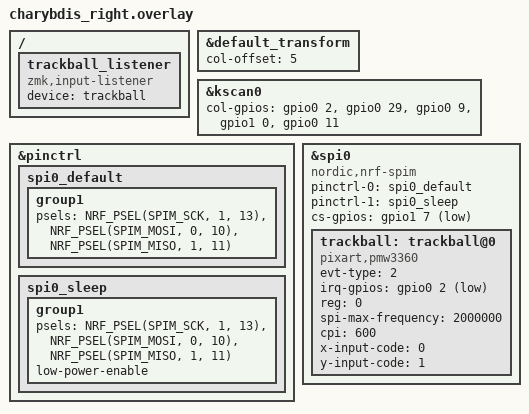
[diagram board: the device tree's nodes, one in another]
// charybdis_right.overlay

#include "charybdis.dtsi"

&default_transform { // The matrix transform for this board is 6 columns over because the left half is 6 columns wide according to the matrix.
    col-offset = <5>;
};

&kscan0 {
    col-gpios
        = <&gpio0 2  (GPIO_ACTIVE_HIGH | GPIO_PULL_DOWN)> // col0 in the schematic
        , <&gpio0 29  (GPIO_ACTIVE_HIGH | GPIO_PULL_DOWN)> // col1 in the schematic
        , <&gpio0 9 (GPIO_ACTIVE_HIGH | GPIO_PULL_DOWN)> // col2 in the schematic
        , <&gpio1 0  (GPIO_ACTIVE_HIGH | GPIO_PULL_DOWN)> // col3 in the schematic
        , <&gpio0 11 (GPIO_ACTIVE_HIGH | GPIO_PULL_DOWN)> // col4 in the schematic
        ;
};


&pinctrl {
    spi0_default: spi0_default {
        group1 {
            psels = <NRF_PSEL(SPIM_SCK, 1, 13)>,
                    <NRF_PSEL(SPIM_MOSI, 0, 10)>,
                    <NRF_PSEL(SPIM_MISO, 1, 11)>;
        };
    };

    spi0_sleep: spi0_sleep {
        group1 {
            psels = <NRF_PSEL(SPIM_SCK, 1, 13)>,
                    <NRF_PSEL(SPIM_MOSI, 0, 10)>,
                    <NRF_PSEL(SPIM_MISO, 1, 11)>;
            low-power-enable;
        };
    };
};

&spi0 {
    status = "okay";
    compatible = "nordic,nrf-spim";
    pinctrl-0 = <&spi0_default>;
    pinctrl-1 = <&spi0_sleep>;
    pinctrl-names = "default", "sleep";
    cs-gpios = <&gpio1 7 GPIO_ACTIVE_LOW>;

    trackball: trackball@0 {
        status = "okay";
        evt-type = <2>; //<INPUT_EV_REL>
        irq-gpios = <&gpio0 2 (GPIO_ACTIVE_LOW | GPIO_PULL_UP)>;
        compatible = "pixart,pmw3360";
        reg = <0>;
        spi-max-frequency = <2000000>;
        cpi = <600>;
        x-input-code = <0>; //<INPUT_REL_X>;
        y-input-code = <1>; //<INPUT_REL_Y>;
    };
};

/ {
  trackball_listener {
    compatible = "zmk,input-listener";
    device = <&trackball>;
  };
};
